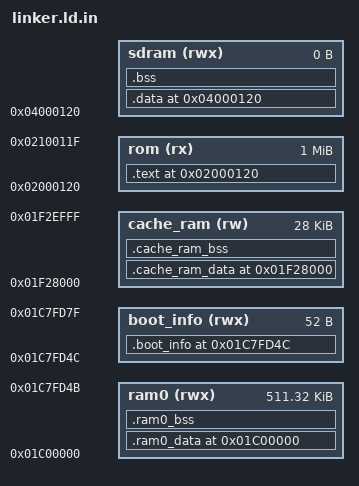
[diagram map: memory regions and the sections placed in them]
/* FM1 linker layout. Project-owned portions follow LICENSE.md.
 * SDK-specific material retains its applicable terms in THIRD_PARTY.md. */
ENTRY(_start)

EXTERN(
    _start
    sdfile_vfs_ops
    clock_timer1
    clock_port
    audio_server_info
    @SBC_DECODER@
)
BOOT_INFO_SIZE = 52;
TLB_SIZE = 0;
SDRAM_SIZE = 0;
RAM0_SIZE = 0x1c7fe00 - 0x1c00000 - TLB_SIZE - BOOT_INFO_SIZE - 128;
UPDATA_BEG = 0x1c7fe00 - 128;
FREE_DACHE_WAY = 7;
FREE_IACHE_WAY = 0;
CACHE_RAM_SIZE = FREE_DACHE_WAY * 4K + FREE_IACHE_WAY * 4K;

MEMORY
{
    rom(rx) : ORIGIN = 0x2000120, LENGTH = (1024 * 1024)
    sdram(rwx) : ORIGIN = 0x4000120, LENGTH = SDRAM_SIZE
    ram0(rwx) : ORIGIN = 0x1c00000 + TLB_SIZE, LENGTH = RAM0_SIZE
    boot_info(rwx) : ORIGIN = 0x1c00000 + TLB_SIZE + RAM0_SIZE, LENGTH = BOOT_INFO_SIZE
    cache_ram(rw) : ORIGIN = 0x1f20000 + (8 - FREE_IACHE_WAY) * 4K, LENGTH = CACHE_RAM_SIZE
}

SECTIONS
{
    . = ORIGIN(rom);
    .text ALIGN(4):
    {
        _text_rodata_begin = .;
        PROVIDE(text_rodata_begin = .);
        KEEP(*startup.S.o*(.text))
        *(.boot_code .boot_code.*)
        *(.text*)
        *(.bt_profile_minimal_stubs.text*)
        *(.rodata*)
        *(.data.rel.ro .data.rel.ro.*)
        . = ALIGN(4);
        *(.LOG_TAG_CONST*)
        *(.fat_data_code)
        . = ALIGN(4);
        *(.update_const)
        *(.update_code .update_code.*)
        *(.bt_updata_ram_code .bt_updata_ram_code.*)
        . = ALIGN(4);
        __VERSION_BEGIN = .;
        KEEP(*(.sys.version))
        __VERSION_END = .;
        *(.dlmalloc_code .dlmalloc_code.*)
        *(.dlmalloc_const)
        *(.mem_heap_code .mem_heap_code.*)
        *(.mem_heap_const)
        *(.os_code .os_code.*)
        *(.os_const)
        *(.os_str)
        *(.os_critical_code .os_critical_code.*)
        *(.os_port_code)
        *(.os_port_const)
        *(.crypto_ecdh_code)
        *(.crypto_ecdh_const)
        *(.crypto_bigint_code .crypto_bigint_code.*)
        *(.crypto_bigint_const)
        *(.crypto_code .crypto_code.*)
        *(.crypto_const)
        *(.ECDH_sample_code)
        *(.ECDH_sample_const)
        *(.uECC_code .uECC_code.*)
        *(.uECC_const)
        *(.hmac_code .hmac_code.*)
        *(.hmac_const)
        *(.hash_sample_code)
        *(.hash_sample_const)
        *(.aes_cmac_sample_code)
        *(.aes_cmac_sample_const)
        *(.jlsp_code)
        . = ALIGN(4);
        *(.jlsp_const)
        *(.crossOver_sparse_code)
        *(.sbc_eng_code .sbc_eng_code.*)
        . = ALIGN(4);
        *(.bt_rf_const)
        *(.bt_rf_code .bt_rf_code.*)
        *(.vendor_manager_const)
        *(.vendor_manager_code .vendor_manager_code.*)
        *(.device_manager_const)
        *(.device_manager_code)
        *(.hci_controller_const)
        *(.hci_controller_code .hci_controller_code.*)
        *(.hci_interface_const)
        *(.hci_interface_code .hci_interface_code.*)
        *(.ble_rf_const)
        *(.ble_rf_code .ble_rf_code.*)
        *(.ble_ll_const)
        *(.ble_ll_code .ble_ll_code.*)
        *(.ble_hci_const)
        *(.ble_hci_code .ble_hci_code.*)
        *(.bredr_irq)
        *(.bredr_irq_code)
        *(.bredr_irq_const)
        *(.classic_lmp_const)
        *(.classic_lmp_linkbulk_const)
        *(.classic_lmp_code .classic_lmp_code.*)
        *(.classic_lmp_linkbulk_code)
        *(.classic_hci_const)
        *(.classic_hci_code)
        *(.classic_lmp_auth_const)
        *(.classic_lmp_bigint_const)
        *(.classic_lmp_crypt_const)
        *(.classic_lmp_ecdh_const)
        *(.classic_lmp_hmac_const)
        *(.classic_lmp_auth_code .classic_lmp_auth_code.*)
        *(.classic_lmp_bigint_code)
        *(.classic_lmp_crypt_code)
        *(.classic_lmp_ecdh_code)
        *(.classic_lmp_hmac_code)
        *(.classic_rf_const)
        *(.classic_rf_code .classic_rf_code.*)
        *(.classic_bb_const)
        *(.classic_bb_code)
        . = ALIGN(4);
        *(.classic_tws_const)
        *(.classic_tws_code .classic_tws_code.*)
        *(.classic_tws_code.esco)
        *(.tws_media_sync_code)
        *(.tws_media_sync_const)
        *(.tws_data_forward_code)
        *(.tws_data_forward_const)
        . = ALIGN(4);
        tws_func_stub_begin = .;
        KEEP(*(.tws_func_stub))
        tws_func_stub_end = .;
        *(.lmp_irq_code .lmp_irq_code.*)
        *(.link_bulk_code .link_bulk_code.*)
        *(.frame_irq_code)
        . = ALIGN(4);
        *(.link_task_const)
        *(.link_task_code .link_task_code.*)
        . = ALIGN(4);
        *(.classic_irq_const)
        *(.classic_irq_code)
        . = ALIGN(4);
        *(.tws_irq_code)
        . = ALIGN(4);
        a2dp_sink_media_codec_begin = .;
        KEEP(*(.a2dp_sink_media_codec))
        a2dp_sink_media_codec_end = .;
        a2dp_event_handler_begin = .;
        KEEP(*(.a2dp_event_handler))
        a2dp_event_handler_end = .;
        sdp_record_item_begin = .;
        KEEP(*(.sdp_record_item))
        sdp_record_item_end = .;
        bt_sleep_begin = .;
        KEEP(*(.bt_sleep))
        bt_sleep_end = .;
        *(.bt_stack_const)
        *(.bt_stack_code .bt_stack_code.*)
        *(.ble_db_const)
        *(.ble_db_code .ble_db_code.*)
        *(.ble_sm_const)
        *(.ble_sm_code .ble_sm_code.*)
        *(.ble_att_const)
        *(.ble_att_code .ble_att_code.*)
        *(.ble_gatt_const)
        *(.ble_gatt_code .ble_gatt_code.*)
        . = ALIGN(4);
        vfs_ops_begin = .;
        KEEP(*(.vfs_operations))
        vfs_ops_end = .;
        initcall_begin = .;
        KEEP(*(.initcall))
        initcall_end = .;
        early_initcall_begin = .;
        KEEP(*(.early.initcall))
        early_initcall_end = .;
        late_initcall_begin = .;
        KEEP(*(.late.initcall))
        late_initcall_end = .;
        platform_initcall_begin = .;
        KEEP(*(.platform.initcall))
        platform_initcall_end = .;
        module_initcall_begin = .;
        KEEP(*(.module.initcall))
        module_initcall_end = .;
        sys_event_handler_begin = .;
        KEEP(*(.sys_event.*))
        sys_event_handler_end = .;
        syscfg_ops_begin = .;
        KEEP(*(.syscfg.2.ops))
        KEEP(*(.syscfg.1.ops))
        KEEP(*(.syscfg.0.ops))
        syscfg_ops_end = .;
        device_node_begin = .;
        *(.device)
        device_node_end = .;
        lp_target_begin = .;
        KEEP(*(.lp_target))
        lp_target_end = .;
        . = ALIGN(4);
        audio_decoder_begin = .;
        KEEP(*(.audio_decoder))
        audio_decoder_end = .;
        audio_hwaccel_begin = .;
        KEEP(*(.audio_hwaccel))
        audio_hwaccel_end = .;
        . = ALIGN(4);
        *(*.rf.text.cache.L2.rf_trim *.rf.text.cache.L2.rf_trim.*)
        . = ALIGN(32);
        text_rodata_end = .;
    } > rom
    . = ORIGIN(sdram);
    .data ALIGN(32):
    {
        . = ALIGN(4);
    } > sdram
    .bss ALIGN(32):
    {
        . = ALIGN(4);
    } > sdram
    . = ORIGIN(ram0);
    .ram0_data ALIGN(4):
    {
        ram_text_rodata_begin = .;
        *(.vm)
        . = ALIGN(4);
        *(.spi_code .spi_code.*)
        . = ALIGN(4);
        *(.flushinv_icache .flushinv_icache.*)
        *(.volatile_ram_code .volatile_ram_code.*)
        *(*.text.cache.L1)
        *(*.text.cache.L2)
        . = ALIGN(4);
        ram_text_rodata_end = .;
        . = ALIGN(4);
        *(.data .data.*)
        . = ALIGN(4);
        *(.volatile_ram)
        . = ALIGN(32);
        *(.volatile_ram.*)
        *(.non_volatile_ram)
        *(.fft_data)
        *(.deepsleep_target)
        *(.os_data)
        *(.os_port_data)
        . = ALIGN(4);
        *(.bt_rf_data)
        *(.vendor_manager_data)
        *(.device_manager_data)
        *(.hci_controller_data)
        *(.hci_interface_data)
        *(.ble_ll_data)
        *(.ble_hci_data)
        *(.classic_hci_data)
        *(.ble_rf_data)
        *(.classic_lmp_data)
        *(.classic_lmp_auth_data)
        *(.classic_lmp_bigint_data)
        *(.classic_lmp_crypt_data)
        *(.classic_lmp_ecdh_data)
        *(.classic_lmp_linkbulk_data)
        *(.classic_lmp_hmac_data)
        *(.classic_rf_data)
        *(.classic_bb_data)
        . = ALIGN(4);
        *(.bt_stack_data)
        *(.ble_db_data)
        *(.ble_sm_data)
        *(.ble_att_data)
        *(.ble_gatt_data)
        . = ALIGN(4);
    } > ram0
    .ram0_bss ALIGN(4) (NOLOAD):
    {
        . = ALIGN(4);
        *(.bd_base)
        *(.bredr_rxtx_bulk)
        acl_tx_pool = .;
        *(.bredr_tx_bulk)
        acl_tx_pool_end = acl_tx_pool@ACL_TX_EXTRA@;
        . = acl_tx_pool_end;
        acl_rx_pool = .;
        *(.bredr_rx_bulk)
        acl_rx_pool_end = acl_rx_pool@ACL_RX_EXTRA@;
        . = acl_rx_pool_end;
        *(.bt_rf_bss)
        *(.hci_controller_bss)
        *(.hci_interface_bss)
        *(.device_manager_bss)
        *(.vendor_manager_bss)
        *(.ble_hci_bss)
        *(.ble_ll_bss)
        *(.ble_rf_bss)
        *(.classic_rf_bss)
        *(.classic_lmp_bss)
        *(.classic_lmp_auth_bss)
        *(.classic_lmp_bigint_bss)
        *(.classic_lmp_crypt_bss)
        *(.classic_lmp_ecdh_bss)
        *(.classic_lmp_linkbulk_bss)
        *(.classic_lmp_hmac_bss)
        *(.classic_bb_bss)
        *(.classic_hci_bss)
        . = ALIGN(4);
        *(.bt_stack_bss)
        *(.ble_db_bss)
        *(.ble_sm_bss)
        *(.ble_att_bss)
        *(.ble_gatt_bss)
        *(.btstack_pool)
        *(.bss .bss.*)
        *(COMMON)
        *(.mem_heap)
        . = ALIGN(4);
        *(.os_port_bss)
        *(.os_bss)
        *(.update_bss)
        . = ALIGN(4);
        *(.stack_magic)
        *(.stack_magic0)
        . = ALIGN(4);
        stack_info_begin = .;
        *(.fm1_r_9bcb3291137c)
        fm1_r_eba215ed3c8c = .;
        *(.fm1_r_6d8b00c8368b)
        fm1_r_6b2771b0c9d1 = .;
        fm1_r_28595ec21ef3 = .;
        PROVIDE(fm1_r_6ffb656e85e0 = .);
        . += 4096 - 768;
        *(.fm1_r_3b277457f4b1)
        fm1_r_bb112ba9c3ba = .;
        PROVIDE(fm1_r_a57a4008ce12 = .);
        ASSERT(fm1_r_bb112ba9c3ba - fm1_r_28595ec21ef3 == 4096,
               "Unexpected engine workspace size");
        ASSERT(fm1_r_f4157fee5abb == fm1_r_bb112ba9c3ba,
               "Engine startup workspace boundary mismatch");
        fm1_r_c525e103c04b = .;
        *(.fm1_r_c2326398118c)
        fm1_r_060f1197193e = .;
        stack_info_end = .;
        *(.sram)
        . = ALIGN(4);
        usb_data_begin = .;
        *(.usb_h_bss)
        *(.usb_g_bss)
        *(.usb_h_dma)
        *(.usb_config_var)
        *(.usb_msd_dma)
        *(.usb_fifo)
        *(.mass_storage)
        *(.uac_var)
        *(.uac_rx)
        *(.usb_h_udisk)
        *(.cdc_var)
        usb_data_end = .;
        . = ALIGN(4);
    } > ram0
    _HEAP_BEGIN = ALIGN(., 32);
    PROVIDE(HEAP_BEGIN = _HEAP_BEGIN);
    _HEAP_END = 0x1c00000 + RAM0_SIZE - 32;
    PROVIDE(HEAP_END = _HEAP_END);
    _MALLOC_SIZE = _HEAP_END - _HEAP_BEGIN;
    PROVIDE(MALLOC_SIZE = _HEAP_END - _HEAP_BEGIN);
    PROVIDE(RAM_HEAP_BEGIN = 0);
    PROVIDE(RAM_HEAP_END = 0);
    PROVIDE(RAM_MALLOC_SIZE = 0);
    . = ORIGIN(boot_info);
    .boot_info ALIGN(4):
    {
        *(.boot_info)
        . = ALIGN(4);
    } > boot_info
    . = ORIGIN(cache_ram);
    .cache_ram_data ALIGN(4):
    {
        app_begin = .;
        *(.app)
        app_end = .;
        sys_cpu_timer_begin = .;
        KEEP(*(.sys_cpu_timer))
        sys_cpu_timer_end = .;
        clock_critical_handler_begin = .;
        KEEP(*(.clock_critical_txt))
        clock_critical_handler_end = .;
        . = ALIGN(4);
    } > cache_ram
    .cache_ram_bss ALIGN(4):
    {
        *(.memp_memory_x)
        . = ALIGN(4);
    } > cache_ram
}
text_begin = ADDR(.text);
text_size = SIZEOF(.text);
bss_begin = ADDR(.bss);
bss_size = SIZEOF(.bss);
data_vma = ADDR(.data);
data_lma = text_begin + SIZEOF(.text);
data_size = SIZEOF(.data);
_ram0_bss_vma = ADDR(.ram0_bss);
_ram0_bss_size = SIZEOF(.ram0_bss);
_ram0_data_vma = ADDR(.ram0_data);
_ram0_data_lma = text_begin + SIZEOF(.text) + SIZEOF(.data);
_ram0_data_size = SIZEOF(.ram0_data);
PROVIDE(cache_ram_bss_vma = ADDR(.cache_ram_bss));
PROVIDE(cache_ram_bss_size = SIZEOF(.cache_ram_bss));
PROVIDE(cache_ram_data_vma = ADDR(.cache_ram_data));
PROVIDE(cache_ram_data_lma = text_begin + SIZEOF(.text) + SIZEOF(.data) + SIZEOF(.ram0_data));
PROVIDE(cache_ram_data_size = SIZEOF(.cache_ram_data));

EXTERN(
    lib_system_version
    lib_btctler_version
    lib_cfg_tool_version
    lib_common_version
    lib_crcm_version
    lib_cryto_toolbox_version
    lib_event_version
    lib_fs_version
    lib_driver_version
    lib_update_version
    lib_wl82_rf_version
)

ASSERT(_start == ORIGIN(rom), "FM1 startup must begin at the fixed ROM entry")
